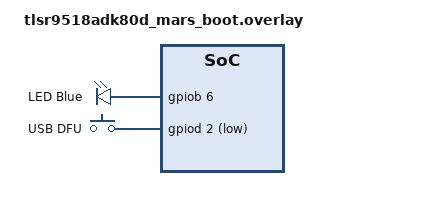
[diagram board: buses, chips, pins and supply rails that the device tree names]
/ {
	leds {
		/delete-node/ led_0;

		led_blue: led_0 {
			label = "LED Blue";
			gpios = <&gpiob 6 GPIO_ACTIVE_HIGH>;
		};
	};

	keys {
		/delete-node/ button_dfu;

		key_dfu: button_dfu {
			label = "USB DFU";
			gpios = <&gpiod 2 (GPIO_PULL_UP | GPIO_ACTIVE_LOW)>;
		};
	};
};

&gpioc {
	interrupts = <38 1>;
};

&gpiod {
	interrupts = <37 1>;
	status = "okay";
};
